# MPU_MA_WP register map
Vendor: Texas Instruments
Peripheral module from a debugger description file (folder TDA2Ex).
Registers are 32-bit, read-only, reset 0x0 unless marked. A register's access mark holds for its fields unless they carry their own. Offsets are as the file gives them; lines under a group give offsets from that group; [hi:lo] are bit positions; {n}, {i} and the like mark numbered series; 'fields as' and 'values as' point back to an identical list; <NAME> marks a mode.

## MPU_MA_WP
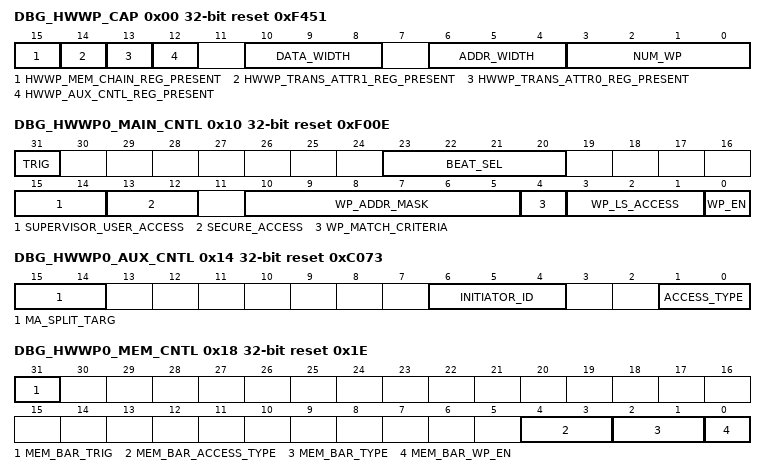
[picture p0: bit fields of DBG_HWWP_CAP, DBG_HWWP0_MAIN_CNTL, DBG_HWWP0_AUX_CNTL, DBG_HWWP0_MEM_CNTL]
0x00 DBG_HWWP_CAP reset 0xF451 — Debug Watchpoint Capabilities Register
  [15] HWWP_MEM_CHAIN_REG_PRESENT — Memory Barrier Chain Control Register implementation0x0: Not present 0x1: Present
  [14] HWWP_TRANS_ATTR1_REG_PRESENT — Transaction Attribute 1 Register implementation0x0: Not present 0x1: Present
  [13] HWWP_TRANS_ATTR0_REG_PRESENT — Transaction Attribute 0 Register implementation0x0: Not present 0x1: Present
  [12] HWWP_AUX_CNTL_REG_PRESENT — Auxillary Control Register implementation0x0: Not present 0x1: Present
  [10:8] DATA_WIDTH — Data Bus Width 0x0: 8 bits 0x1: 16 bits 0x2: 32 bits 0x3: 64 bits 0x4: 128 bits All other values: Reserved
  [6:4] ADDR_WIDTH — Address Bus Width0x0: 8 bits 0x1: 16 bits 0x2: 24 bits 0x3: 32 bits 0x4: 36 bits 0x5: 40 bits 0x6: 64 bits 0x7: Reserved
  [3:0] NUM_WP — Number of Watchpoints supported (0-15)
0x04 TRIG_CTRL access per field — Trigger Control Register
  [0] TRIG_EN rw — 0x0: Trigger disabled. Trigger output (MA_WP_TRIGGER) will not fire0x1: Trigger enabled. Trigger output (MA_WP_TRIGGER) will fire
0x08 DBG_HWWP0_LW_ADDR0 rw — Debug Watchpoint Addr0 Register (lower order bits 31:0).This register should be written only when WP_EN=0.
  [31:0] LOWER_ORDER_WP_ADDR — The byte-addressable lower order AXI-4 physical watchpoint address to monitor
0x0C DBG_HWWP0_HG_ADDR0 access per field — Debug Watchpoint Addr0 Register (higher order bits 39:32).This register should be written only when WP_EN=0.
  [7:0] HIGHER_ORDER_WP_ADDR rw — The byte-addressable higher order AXI-4 physical watchpoint address to monitor
0x10 DBG_HWWP0_MAIN_CNTL access per field reset 0xF00E — Debug Watchpoint Main Control Register
  [31] TRIG ro — Watchpoint trigger0x0: Watchpoint not triggered0x1: Watchpoint has triggered (Reset upon 0-&gt;1 transition of WP_EN)
  [23:20] BEAT_SEL rw — Beat Select(This parameter decides upon for which beat of the burst the data byte lanes should be captured data)
  [15:14] SUPERVISOR_USER_ACCESS rw — Supervisor/User access0x0: Reserved 0x1: User 0x2: Supervisor 0x3: No preference
  [13:12] SECURE_ACCESS rw — Secure/Non-secure access0x0: Reserved 0x1: Non-secure 0x2: Secure. Not supported on GP device0x3: No preference
  [10:5] WP_ADDR_MASK rw — Watchpoint address mask (bits to ignore)0x0: Ignore address bit 0.....0x27: Ignore address bit 390x28 – 0x3F: Reserved
  [4] WP_MATCH_CRITERIA rw — Watchpoint match criteria0x0: Match if access within address range to include MIN and MAX 0x1: Match if access outside address range
  [3:1] WP_LS_ACCESS rw — Watchpoint Load/Store access0x0: (Load) Load exclusive or swap 0x1: (Store) Store exclusive or swap (non-posted) 0x2: (Store) Store exclusive or swap (posted) 0x3: Any type of store 0x4, 0x5, 0x6: Reserved 0x7: No preference (valid only if CHAIN_WP_EN=0; otherwise, reserved) Note: In the case of CHAIN_WP_EN=1, both data and memory barrier watchpoints must have the same transaction type; that is, both must be read or both must be write
  [0] WP_EN rw — Watchpoint enable0x0: Disable the watchpoint0x1: Enable the watchpoint
0x14 DBG_HWWP0_AUX_CNTL access per field reset 0xC073 — Debug Watchpoint Auxilliary Control Register.This register should be written only when WP_EN=0.
  [15:14] MA_SPLIT_TARG rw — MA splitter target0x0: Reserved 0x1: AXI2OCP bridge 0x2: EMIF 0x3: No preference
  [6:4] INITIATOR_ID rw — Initiator ID0x0: CPU_0 0x1: CPU_1. Not supported on this device0x2: CPU_2. Not supported on this device0x3: CPU_3. Not supported on this device0x4: Unknown source (ACP, FEQ, etc) 0x5: CMU. Not supported on this device 0x6: Reserved 0x7: No preference
  [1:0] ACCESS_TYPE rw — Access type0x0: Reserved 0x1: Instructions 0x2: Data/others 0x3: No preference
0x18 DBG_HWWP0_MEM_CNTL access per field reset 0x1E — Debug Watchpoint Memory Barrier Control Register.This register should be written only when WP_EN=0.
  [31] MEM_BAR_TRIG ro — Memory barrier trigger0x0: Memory Barrier Watchpoint not triggered 0x1: Memory Barrier Watchpoint has triggered(Reset upon 0-&gt;1 transition of MEM_BAR_WP_EN)
  [4:3] MEM_BAR_ACCESS_TYPE rw — Type of memory barrier access0x0: Reserved 0x1: Read 0x2: Write 0x3: Don't care (only if CHAIN_WP_EN=0; otherwise, reserved) Note: In the case of CHAIN_WP_EN=1, both memory barrier and data watchpoint must have the same transaction types; that is, both must be read or both must be write
  [2:1] MEM_BAR_TYPE rw — Memory barrier type0x0: Reserved 0x1: DSB 0x2: DMB 0x3: No preference
  [0] MEM_BAR_WP_EN rw — Memory barrier watchpoint enable0x0: Disable the watchpoint0x1: Enable the watchpoint
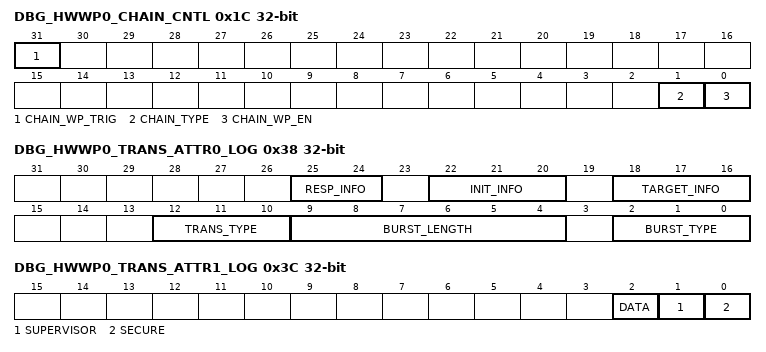
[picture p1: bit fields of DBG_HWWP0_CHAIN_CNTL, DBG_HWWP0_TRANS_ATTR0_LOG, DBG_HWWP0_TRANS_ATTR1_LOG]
0x1C DBG_HWWP0_CHAIN_CNTL access per field — Debug Watchpoint Data/Memory Barrier Chain Control Register.This register should be written only when WP_EN=0.
  [31] CHAIN_WP_TRIG ro — Chained watchpoints (memory barrier and data watchpoint) trigger0x0: Chained Watchpoints not triggered 0x1: Chained Watchpoints have triggered (Reset upon 0-&gt;1 transition of CHAIN_WP_EN)
  [1] CHAIN_TYPE rw — Chain type0x0: Watchpoint match then memory barrier match 0x1: Memory barrier match then watchpoint match
  [0] CHAIN_WP_EN rw — Chained watchpoints (memory barrier and data watchpoint) enable0x0: Disable the chained watchpoints0x1: Enable the chained watchpointsNote: Both the memory barrier and data watchpoint should be enabled subsequent to this to avoid partial match/race conditions
0x20 DBG_HWWP0_LW_ADDR0_LOG — Debug Watchpoint Addr0 Log Register (lower order bits 31:0).This register should be read only when TRIG=1 or WP_EN=0.This register is reset upon 0->1 transition of WP_EN.
  [31:0] WP_ADDR_LOWER_ORDER_BITS — Watchpoint address lower order bits (bits 31:0)(The byte-addressable lower order AXI-4 physical watchpoint address bits which results in a match)
0x24 DBG_HWWP0_HG_ADDR0_LOG — Debug Watchpoint Addr0 Log Register (higher order bits 39:32).This register should be read only when TRIG=1 or WP_EN=0.This register is reset upon 0->1 transition of WP_EN.
  [7:0] WP_ADDR_HIGHER_ORDER_BITS — Watchpoint address higher order bits (bits 39:32)(The byte-addressable higher order AXI-4 physical watchpoint address bits which results in a match)
{0x28+4i} DBG_HWWP0_DATA{i}_LOG (i=0..2) — Debug Watchpoint Data Log Register (bits {32i+31}:{32i}).This register should be read only when TRIG=1 or WP_EN=0.This register is reset upon 0->1 transition of WP_EN.
  [31:0] DATA{i}_CAPTURE — Data capture (bits {32i+31}:{32i})(32-bit data associated with the access which results in a watchpoint match)
0x34 DBG_HWWP0_DATA3_LOG — Debug Watchpoint Data Log Register (bits 127:96).This register should be read only when TRIG=1 or WP_EN=0.This register is reset upon 0->1 transition of WP_EN.
  [31:0] DATA3_CAPTURE — Data capture (bits 127:96) (32-bit data associated with the access which results in a watchpoint match)
0x38 DBG_HWWP0_TRANS_ATTR0_LOG — Debug Watchpoint Transaction Attributes 0 Log Register.This register should be read only when TRIG=1 or WP_EN=0.This register is reset upon 0->1 transition of WP_EN.
  [25:24] RESP_INFO — Response info0x0: Reserved 0x1: Okay 0x2: Request failed 0x3: Request error
  [22:20] INIT_INFO — Initiator info0x0: CPU_0 0x1: CPU_1. Not supported on this device0x2: CPU_2. Not supported on this device0x3: CPU_3. Not supported on this device0x4: Unknown source (ACP, FEQ, etc) 0x5: CMU. Not supported on this device 0x6, 0x7: Reserved
  [18:16] TARGET_INFO — Target info0x0: AXI2OCP 0x1: EMIF All other values: Reserved
  [12:10] TRANS_TYPE — Transaction type(The type of transaction which results in a watchpoint match and is protocol independent. Not all protocols support all transaction types)0x0: Reserved 0x1: Write posted 0x2: Read 0x3: Read exclusive 0x4: Read linked 0x5: Write non-posted 0x6: Write conditional 0x7: Broadcast
  [9:4] BURST_LENGTH — Burst length(The length of the burst which results in a watchpoint match) 0x1: Burst length = 1 (min value)0x2: Burst length = 2.....0x3F: Burst length = 63 (max value)
  [2:0] BURST_TYPE — Burst type0x0: Incrementing 0x1: Wrapping 0x3: Fixed (streaming) All other values: Reserved
0x3C DBG_HWWP0_TRANS_ATTR1_LOG — Debug Watchpoint Transaction Attributes 1 Log Register.This register should be read only when TRIG=1 or WP_EN=0.This register is reset upon 0->1 transition of WP_EN.
  [2] DATA — Data access/Instruction fetch0x0: Other, data, PLE, eviction 0x1: Instruction
  [1] SUPERVISOR — Supervisor/User access0x0: User 0x1: Supervisor
  [0] SECURE — Secure/Non-secure access0x0: Non-secure 0x1: Secure. Not supported on GP device
0x40 DBG_HWWP0_DATA_TRANS_ATTR0_LOG — Debug Watchpoint Data Transaction Attributes 0 Log Register.This register should be read only when TRIG=1 or WP_EN=0.This register is reset upon 0->1 transition of WP_EN.
  [15:0] BYTE_EN — Byte enable(Byte enables for the 128-bit of data captured for the transaction match)
